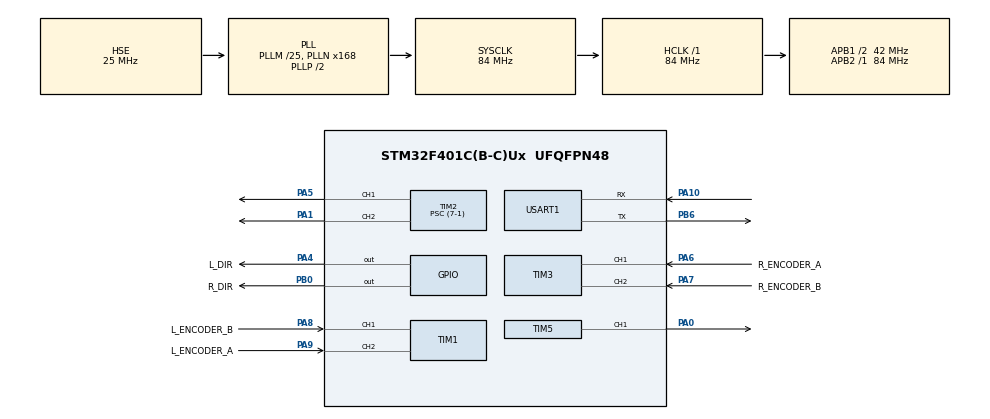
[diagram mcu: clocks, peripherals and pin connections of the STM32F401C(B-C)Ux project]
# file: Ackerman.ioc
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Mcu.Family=STM32F4
Mcu.Name=STM32F401C(B-C)Ux
Mcu.Package=UFQFPN48
NVIC.PriorityGroup=NVIC_PRIORITYGROUP_4
NVIC.TIM1_BRK_TIM9_IRQn=true\:0\:0\:false\:false\:true\:true\:true\:true
NVIC.TIM4_IRQn=true\:0\:0\:false\:false\:true\:true\:true\:true
NVIC.USART1_IRQn=true\:0\:0\:false\:false\:true\:true\:true\:true
PA0-WKUP.Signal=S_TIM5_CH1
PA1.Signal=S_TIM2_CH2
PA10.Mode=Asynchronous
PA10.Signal=USART1_RX
PA13.Mode=Serial_Wire
PA13.Signal=SYS_JTMS-SWDIO
PA14.Mode=Serial_Wire
PA14.Signal=SYS_JTCK-SWCLK
PA4.GPIO_Label=L_DIR
PA4.Signal=GPIO_Output
PA5.Signal=S_TIM2_CH1_ETR
PA6.GPIO_Label=R_ENCODER_A
PA6.GPIO_PuPd=GPIO_NOPULL
PA6.Signal=S_TIM3_CH1
PA7.GPIO_Label=R_ENCODER_B
PA7.GPIO_PuPd=GPIO_NOPULL
PA7.Signal=S_TIM3_CH2
PA8.GPIO_Label=L_ENCODER_B
PA8.Signal=S_TIM1_CH1
PA9.GPIO_Label=L_ENCODER_A
PA9.Signal=S_TIM1_CH2
PB0.GPIO_Label=R_DIR
PB0.Signal=GPIO_Output
PB6.Mode=Asynchronous
PB6.Signal=USART1_TX
PH0\ -\ OSC_IN.Mode=HSE-External-Oscillator
PH0\ -\ OSC_IN.Signal=RCC_OSC_IN
PH1\ -\ OSC_OUT.Mode=HSE-External-Oscillator
PH1\ -\ OSC_OUT.Signal=RCC_OSC_OUT
ProjectManager.HeapSize=0x200
ProjectManager.StackSize=0x400
ProjectManager.TargetToolchain=MDK-ARM V5.32
RCC.48MHZClocksFreq_Value=42000000
RCC.AHBFreq_Value=84000000
RCC.APB1CLKDivider=RCC_HCLK_DIV2
RCC.APB1Freq_Value=42000000
RCC.APB1TimFreq_Value=84000000
RCC.APB2Freq_Value=84000000
RCC.APB2TimFreq_Value=84000000
RCC.CortexFreq_Value=84000000
RCC.HCLKFreq_Value=84000000
RCC.HSE_VALUE=25000000
RCC.HSI_VALUE=16000000
RCC.LSE_VALUE=32768
RCC.PLLM=25
RCC.PLLN=168
RCC.PLLSourceVirtual=RCC_PLLSOURCE_HSE
RCC.SYSCLKFreq_VALUE=84000000
RCC.SYSCLKSource=RCC_SYSCLKSOURCE_PLLCLK
RCC.VCOOutputFreq_Value=168000000
SH.S_TIM1_CH1.0=TIM1_CH1,Encoder_Interface
SH.S_TIM1_CH2.0=TIM1_CH2,Encoder_Interface
SH.S_TIM2_CH1_ETR.0=TIM2_CH1,PWM Generation1 CH1
SH.S_TIM2_CH2.0=TIM2_CH2,PWM Generation2 CH2
SH.S_TIM3_CH1.0=TIM3_CH1,Encoder_Interface
SH.S_TIM3_CH2.0=TIM3_CH2,Encoder_Interface
SH.S_TIM5_CH1.0=TIM5_CH1,PWM Generation1 CH1
TIM1.EncoderMode=TIM_ENCODERMODE_TI12
TIM1.IC1Filter=10
TIM1.IC2Filter=10
TIM2.Channel-PWM\ Generation1\ CH1=TIM_CHANNEL_1
TIM2.Channel-PWM\ Generation2\ CH2=TIM_CHANNEL_2
TIM2.Period=(160-1)
TIM2.Prescaler=(7-1)
TIM3.EncoderMode=TIM_ENCODERMODE_TI12
TIM3.IC1Filter=0
TIM3.IC2Filter=0
TIM4.Period=10000-1
TIM4.Prescaler=83
TIM4.TIM_MasterOutputTrigger=TIM_TRGO_UPDATE
TIM5.Channel-PWM\ Generation1\ CH1=TIM_CHANNEL_1
TIM5.Period=20000-1
TIM5.Prescaler=84-1
TIM5.Pulse-PWM\ Generation1\ CH1=1500-1
TIM9.Period=20000-1
TIM9.Prescaler=83
USART1.VirtualMode=VM_ASYNC
VP_TIM2_VS_ClockSourceINT.Mode=Internal
VP_TIM4_VS_ClockSourceINT.Mode=Internal
VP_TIM5_VS_ClockSourceINT.Mode=Internal
VP_TIM9_VS_ClockSourceINT.Mode=Internal
board=custom

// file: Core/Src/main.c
/* USER CODE BEGIN Header */
/**
  ******************************************************************************
  * @file           : main.c
  * @brief          : Main program body
  ******************************************************************************
  * @attention
  *
  * Copyright (c) 2025 STMicroelectronics.
  * All rights reserved.
  *
  * This software is licensed under terms that can be found in the LICENSE file
  * in the root directory of this software component.
  * If no LICENSE file comes with this software, it is provided AS-IS.
  *
  ******************************************************************************
  */
/* USER CODE END Header */
#include "main.h"
#include "tim.h"
#include "usart.h"
#include "gpio.h"

/* USER CODE BEGIN Includes */
//#include "JY901.h"
#include "Control.h"
/* USER CODE END Includes */

void SystemClock_Config(void);

/* USER CODE BEGIN 0 */
//float current_angle[3]={0};
//float current_accel[3]={0};
//float current_gyro[3]={0};
/* USER CODE END 0 */

int main(void)
{

  /* MCU Configuration--------------------------------------------------------*/

  /* Reset of all peripherals, Initializes the Flash interface and the Systick. */
  HAL_Init();

  /* Configure the system clock */
  SystemClock_Config();

  /* Initialize all configured peripherals */
  MX_GPIO_Init();
  MX_USART1_UART_Init();
  MX_TIM1_Init();
  MX_TIM2_Init();
  MX_TIM3_Init();
  MX_TIM5_Init();
  MX_TIM4_Init();
  MX_TIM9_Init();
  /* USER CODE BEGIN 2 */
//JY901_Init();			//JY901初始化
//HAL_UARTEx_ReceiveToIdle_DMA(&huart2,jy901s_data.RxBuffer,RXBUFFER_LEN);

HAL_TIM_PWM_Start(&htim2, TIM_CHANNEL_1);
HAL_TIM_PWM_Start(&htim2, TIM_CHANNEL_2);

HAL_TIM_Encoder_Start(&htim1,TIM_CHANNEL_ALL);
HAL_TIM_Encoder_Start(&htim3,TIM_CHANNEL_ALL);

HAL_TIM_PWM_Start(&htim5,TIM_CHANNEL_1);
  /* USER CODE END 2 */

  /* Infinite loop */
  /* USER CODE BEGIN WHILE */
  while (1)
  {
//Motor_Set_Direction(&Left_Motor,Forward);
//for(int i=30;i<80;i+=10){
//TIM2->CCR1=i;
//HAL_Delay(3000);
//}
//for(int i=70;i>20;i-=10){
//TIM2->CCR1=i;
//HAL_Delay(3000);
//}

    /* USER CODE END WHILE */

  }
}

void SystemClock_Config(void)
{
  RCC_OscInitTypeDef RCC_OscInitStruct = {0};
  RCC_ClkInitTypeDef RCC_ClkInitStruct = {0};

  /** Configure the main internal regulator output voltage
  */
  __HAL_RCC_PWR_CLK_ENABLE();
  __HAL_PWR_VOLTAGESCALING_CONFIG(PWR_REGULATOR_VOLTAGE_SCALE2);

  /** Initializes the RCC Oscillators according to the specified parameters
  * in the RCC_OscInitTypeDef structure.
  */
  RCC_OscInitStruct.OscillatorType = RCC_OSCILLATORTYPE_HSE;
  RCC_OscInitStruct.HSEState = RCC_HSE_ON;
  RCC_OscInitStruct.PLL.PLLState = RCC_PLL_ON;
  RCC_OscInitStruct.PLL.PLLSource = RCC_PLLSOURCE_HSE;
  RCC_OscInitStruct.PLL.PLLM = 25;
  RCC_OscInitStruct.PLL.PLLN = 168;
  RCC_OscInitStruct.PLL.PLLP = RCC_PLLP_DIV2;
  RCC_OscInitStruct.PLL.PLLQ = 4;
  if (HAL_RCC_OscConfig(&RCC_OscInitStruct) != HAL_OK)
  {
    Error_Handler();
  }

  /** Initializes the CPU, AHB and APB buses clocks
  */
  RCC_ClkInitStruct.ClockType = RCC_CLOCKTYPE_HCLK|RCC_CLOCKTYPE_SYSCLK
                              |RCC_CLOCKTYPE_PCLK1|RCC_CLOCKTYPE_PCLK2;
  RCC_ClkInitStruct.SYSCLKSource = RCC_SYSCLKSOURCE_PLLCLK;
  RCC_ClkInitStruct.AHBCLKDivider = RCC_SYSCLK_DIV1;
  RCC_ClkInitStruct.APB1CLKDivider = RCC_HCLK_DIV2;
  RCC_ClkInitStruct.APB2CLKDivider = RCC_HCLK_DIV1;

  if (HAL_RCC_ClockConfig(&RCC_ClkInitStruct, FLASH_LATENCY_2) != HAL_OK)
  {
    Error_Handler();
  }
}

/* USER CODE BEGIN 4 */
void HAL_UARTEx_RxEventCallback(UART_HandleTypeDef *huart,uint16_t Size){
if(huart==&huart1){

}

//if(huart==&huart2){
//int i;
//jy901s_data.Rx_len=(uint8_t)Size;
//JY901_Get_Data();
//for(i=0;i<3;i++)
//current_accel[i]=jy901s_data.Accel[i];
//
//for(i=0;i<3;i++)
//current_angle[i]=jy901s_data.Angle[i]*180.0/32767;
//
//for(i=0;i<3;i++)
//current_gyro[i]=jy901s_data.Gyro[i];
//Ackerman_Turning.Yaw=current_angle[2];
//HAL_UARTEx_ReceiveToIdle_DMA(&huart2,jy901s_data.RxBuffer,RXBUFFER_LEN);
//}

}

void HAL_TIM_PeriodElapsedCallback(TIM_HandleTypeDef *htim){
if(htim==&htim4){
Motor_Speed_Control(&Left_Motor);
Motor_Speed_Control(&Right_Motor);
}

if(htim==&htim9){
Car_Control(Ackerman_State);
}

}

/* USER CODE END 4 */

void Error_Handler(void)
{
  __disable_irq();
  while (1)
  {
  }
}
